# STM32MP13xx register map
File version: 1.5
CPU: CA7 r0p0, little endian, MPU, FPU, 4 interrupt priority bits
Registers are 32-bit, read-write, reset 0x0 unless marked. A register's access mark holds for its fields unless they carry their own. Offsets are from the block's base; [hi:lo] are bit positions; {n}, {i} and the like mark numbered series; 'fields as' and 'values as' point back to an identical list.

## RTC
Base 0x5C004000
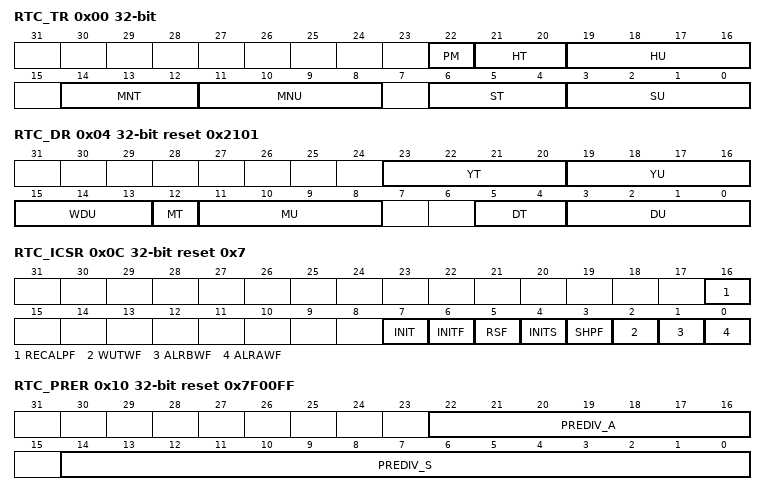
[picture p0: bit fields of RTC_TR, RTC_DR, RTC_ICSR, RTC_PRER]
0x00 RTC_TR — The RTC_TR is the calendar time shadow register. This register must be written in initialization mode only. Refer to Calendar initialization and configuration on page1830 and Reading the calendar on page1831. This register is write protected. The write access procedure is described in RTC register write protection on page1830. This register can be write-protected against non-secure access. Refer to Section50.3.4: RTC secure protection modes.
  [22] PM, [21:20] HT, [19:16] HU, [14:12] MNT, [11:8] MNU, [6:4] ST, [3:0] SU
0x04 RTC_DR reset 0x2101 — The RTC_DR is the calendar date shadow register. This register must be written in initialization mode only. Refer to Calendar initialization and configuration on page1830 and Reading the calendar on page1831. This register is write protected. The write access procedure is described in RTC register write protection on page1830. This register can be write-protected against non-secure access. Refer to Section50.3.4: RTC secure protection modes.
  [23:20] YT, [19:16] YU, [15:13] WDU, [12] MT, [11:8] MU, [5:4] DT, [3:0] DU
0x08 RTC_SSR ro — RTC sub second register
  [15:0] SS
0x0C RTC_ICSR access per field reset 0x7 — This register is write protected. The write access procedure is described in RTC register write protection on page1830. This register can be globally protected, or each bit of this register can be individually protected against non-secure access. Refer to Section50.3.4: RTC secure protection modes.
  [16] RECALPF ro, [7] INIT rw, [6] INITF ro, [5] RSF rw, [4] INITS ro, [3] SHPF ro, [2] WUTWF ro, [1] ALRBWF ro, [0] ALRAWF ro
0x10 RTC_PRER reset 0x7F00FF — This register must be written in initialization mode only. The initialization must be performed in two separate write accesses. Refer to Calendar initialization and configuration on page1830. This register is write protected. The write access procedure is described in RTC register write protection on page1830. This register can be write-protected against non-secure access. Refer to Section50.3.4: RTC secure protection modes.
  [22:16] PREDIV_A, [14:0] PREDIV_S
0x14 RTC_WUTR reset 0xFFFF — This register can be written only when WUTWF is set to 1 in RTC_ICSR. This register is write protected. The write access procedure is described in RTC register write protection on page1830. This register can be protected against non-secure access. Refer to Section50.3.4: RTC secure protection modes.
  [15:0] WUT
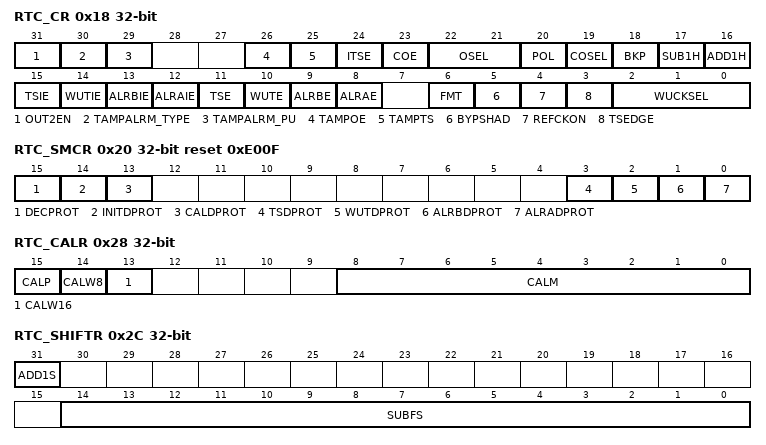
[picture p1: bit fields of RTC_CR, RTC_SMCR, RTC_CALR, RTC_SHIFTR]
0x18 RTC_CR access per field — This register is write protected. The write access procedure is described in RTC register write protection on page1830. This register can be globally protected, or each bit of this register can be individually protected against non-secure access. Refer to Section50.3.4: RTC secure protection modes.
  [31] OUT2EN rw, [30] TAMPALRM_TYPE rw, [29] TAMPALRM_PU rw, [26] TAMPOE rw, [25] TAMPTS rw, [24] ITSE rw, [23] COE rw, [22:21] OSEL rw, [20] POL rw, [19] COSEL rw, [18] BKP rw, [17] SUB1H wo, [16] ADD1H wo, [15] TSIE rw, [14] WUTIE rw, [13] ALRBIE rw, [12] ALRAIE rw, [11] TSE rw, [10] WUTE rw, [9] ALRBE rw, [8] ALRAE rw, [6] FMT rw, [5] BYPSHAD rw, [4] REFCKON rw, [3] TSEDGE rw, [2:0] WUCKSEL rw
0x20 RTC_SMCR reset 0xE00F — This register can be written only when the APB access is secure.
  [15] DECPROT, [14] INITDPROT, [13] CALDPROT, [3] TSDPROT, [2] WUTDPROT, [1] ALRBDPROT, [0] ALRADPROT
0x24 RTC_WPR wo — RTC write protection register
  [7:0] KEY
0x28 RTC_CALR — This register is write protected. The write access procedure is described in RTC register write protection on page1830. This register can be write-protected against non-secure access. Refer to Section50.3.4: RTC secure protection modes.
  [15] CALP, [14] CALW8, [13] CALW16, [8:0] CALM
0x2C RTC_SHIFTR wo — This register is write protected. The write access procedure is described in RTC register write protection on page1830. This register can be protected against non-secure access. Refer to Section50.3.4: RTC secure protection modes.
  [31] ADD1S, [14:0] SUBFS
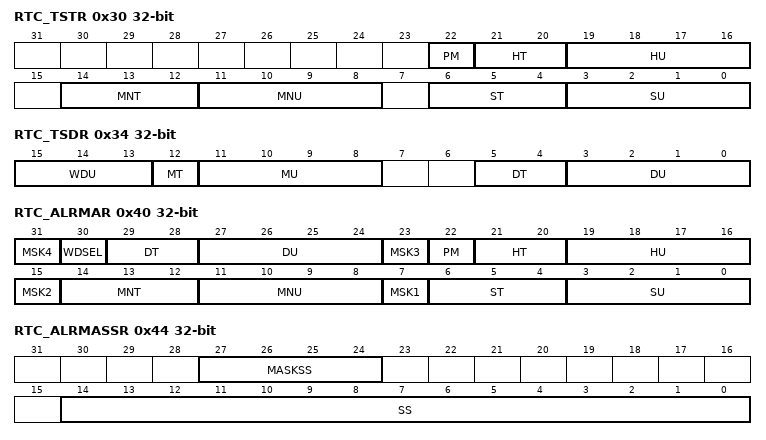
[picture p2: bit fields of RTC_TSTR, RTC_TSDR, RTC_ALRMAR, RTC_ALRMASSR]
0x30 RTC_TSTR ro — The content of this register is valid only when TSF is set to 1 in RTC_SR. It is cleared when TSF bit is reset. This register can be protected against non-secure access. Refer to Section50.3.4: RTC secure protection modes.
  fields as RTC_TR
0x34 RTC_TSDR ro — The content of this register is valid only when TSF is set to 1 in RTC_SR. It is cleared when TSF bit is reset. This register can be protected against non-secure access. Refer to Section50.3.4: RTC secure protection modes.
  [15:13] WDU, [12] MT, [11:8] MU, [5:4] DT, [3:0] DU
0x38 RTC_TSSSR ro — The content of this register is valid only when TSF is set to 1 in RTC_SR. It is cleared when the TSF bit is reset. This register can be protected against non-secure access. Refer to Section50.3.4: RTC secure protection modes.
  [15:0] SS
0x40 RTC_ALRMAR — This register can be written only when ALRAWF is set to 1 in RTC_ICSR, or in initialization mode. This register is write protected. The write access procedure is described in RTC register write protection on page1830. This register can be protected against non-secure access. Refer to Section50.3.4: RTC secure protection modes.
  [8n-1] MSK{n} (n=1..4), [30] WDSEL, [29:28] DT, [27:24] DU, [22] PM, [21:20] HT, [19:16] HU, [14:12] MNT, [11:8] MNU, [6:4] ST, [3:0] SU
0x44 RTC_ALRMASSR — This register can be written only when ALRAWF is set to 1 in RTC_ICSR, or in initialization mode. This register is write protected. The write access procedure is described in RTC register write protection on page1830. This register can be protected against non-secure access. Refer to Section50.3.4: RTC secure protection modes.
  [27:24] MASKSS, [14:0] SS
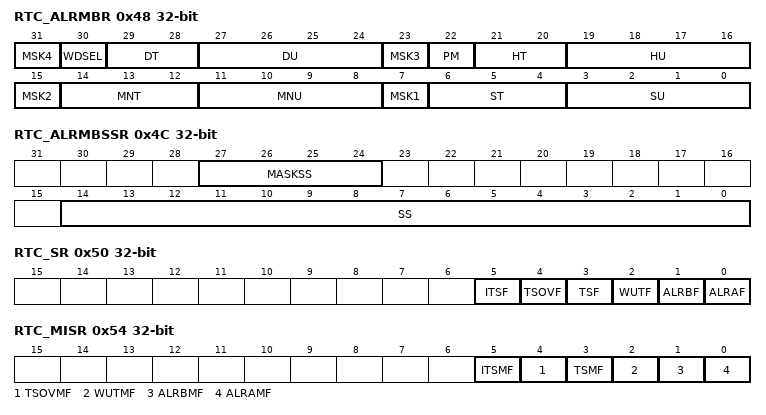
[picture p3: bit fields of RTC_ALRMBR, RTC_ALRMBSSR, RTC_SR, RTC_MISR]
0x48 RTC_ALRMBR — This register can be written only when ALRBWF is set to 1 in RTC_ICSR, or in initialization mode. This register is write protected. The write access procedure is described in RTC register write protection on page1830. This register can be protected against non-secure access. Refer to Section50.3.4: RTC secure protection modes.
  fields as RTC_ALRMAR
0x4C RTC_ALRMBSSR — This register can be written only when ALRBE is reset in RTC_CR register, or in initialization mode. This register is write protected.The write access procedure is described in Section: RTC register write protection. This register can be protected against non-secure access. Refer to Section50.3.4: RTC secure protection modes.
  [27:24] MASKSS, [14:0] SS
0x50 RTC_SR ro — This register can be protected against non-secure access. Refer to Section50.3.4: RTC secure protection modes.
  [5] ITSF, [4] TSOVF, [3] TSF, [2] WUTF, [1] ALRBF, [0] ALRAF
0x54 RTC_MISR ro — RTC non-secure masked interrupt status register
  [5] ITSMF, [4] TSOVMF, [3] TSMF, [2] WUTMF, [1] ALRBMF, [0] ALRAMF
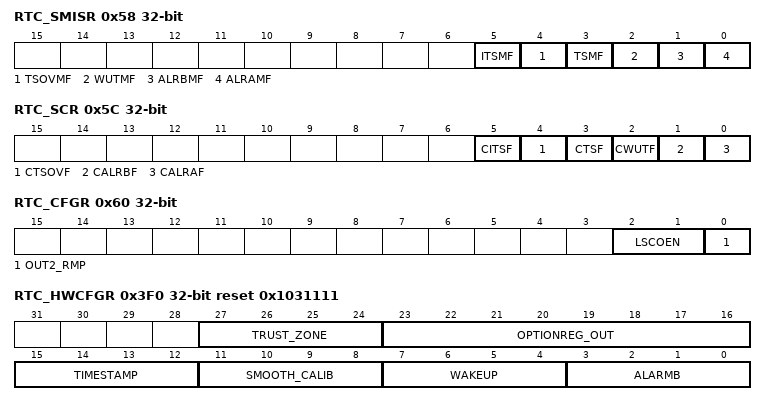
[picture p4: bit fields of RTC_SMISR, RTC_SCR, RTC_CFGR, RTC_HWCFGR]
0x58 RTC_SMISR ro — This register can be protected against non-secure access. Refer to Section50.3.4: RTC secure protection modes.
  [5] ITSMF, [4] TSOVMF, [3] TSMF, [2] WUTMF, [1] ALRBMF, [0] ALRAMF
0x5C RTC_SCR wo — This register can be protected against non-secure access. Refer to Section50.3.4: RTC secure protection modes.
  [5] CITSF, [4] CTSOVF, [3] CTSF, [2] CWUTF, [1] CALRBF, [0] CALRAF
0x60 RTC_CFGR — RTC configuration register
  [2:1] LSCOEN, [0] OUT2_RMP
0x3F0 RTC_HWCFGR ro reset 0x1031111 — RTC hardware configuration register
  [27:24] TRUST_ZONE, [23:16] OPTIONREG_OUT, [15:12] TIMESTAMP, [11:8] SMOOTH_CALIB, [7:4] WAKEUP, [3:0] ALARMB
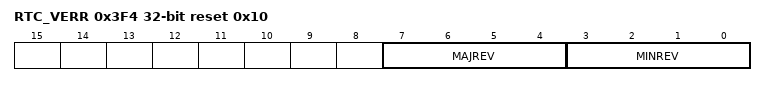
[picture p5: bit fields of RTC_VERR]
0x3F4 RTC_VERR ro reset 0x10 — RTC version register
  [7:4] MAJREV, [3:0] MINREV
0x3F8 RTC_IPIDR ro reset 0x120033 — RTC identification register
  [31:0] ID
0x3FC RTC_SIDR ro reset 0xA3C5DD01 — RTC size identification register
  [31:0] SID
